# RN831X_RN861X_MCU register map
File version: v0.0.1
CPU: RN831X_RN861X_MCU r1p0, little endian, MPU, no FPU
Registers are 32-bit, read-write, reset 0x0 unless marked. A register's access mark holds for its fields unless they carry their own. Offsets are from the block's base; [hi:lo] are bit positions; {n}, {i} and the like mark numbered series.

## CAN_CORE0 — Controller Area Network Module
Base 0x20058000
Same registers: CAN_CORE1 0xA0058000
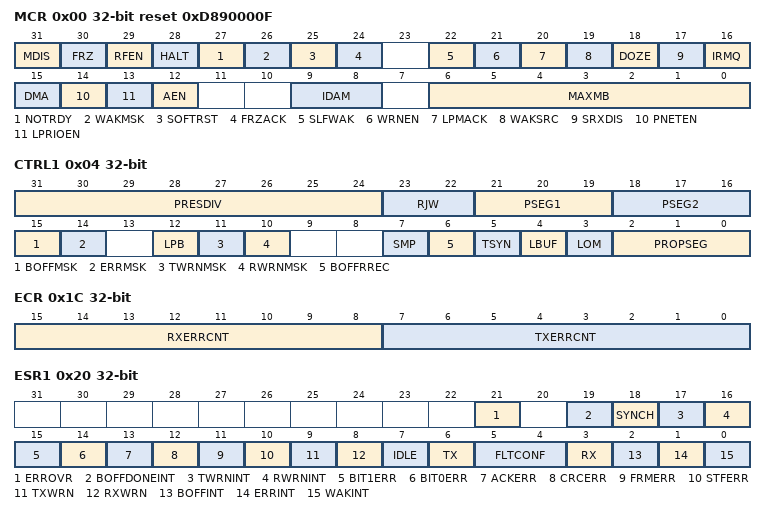
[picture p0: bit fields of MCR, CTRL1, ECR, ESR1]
0x00 MCR reset 0xD890000F — CAN Module Configuration Register.
  [31] MDIS — Disable the CAN module as well as the clocks to the PE and CHI submodules.
  [30] FRZ — Enabled to enter Freeze mode.
  [29] RFEN — Enable Rx FIFO.
  [28] HALT — Enter Freeze mode if the FRZ bit is asserted.
  [27] NOTRDY — CAN is either in Disable or Freeze mode.
  [26] WAKMSK — Enable Wake-up Interrupt.
  [25] SOFTRST — Soft reset.
  [24] FRZACK — Freeze Mode Acknowledge.
  [22] SLFWAK — Wake-up byself Enable.
  [21] WRNEN — Warning Interrupt Enable.
  [20] LPMACK — Low-Power Mode Acknowledge.
  [19] WAKSRC
  [18] DOZE — Enable sleep mode.
  [17] SRXDIS — Disable self reception.
  [16] IRMQ — Enable individual Rx masking and queue feature.
  [15] DMA — Enable DMA feature for Rx FIFO.
  [14] PNETEN — Enable Pretended Network.
  [13] LPRIOEN — Enable Local Priority.
  [12] AEN — Enable abort.
  [9:8] IDAM — The format of the Rx FIFO ID Filter Table elements.
    0=One full ID (standard and extended) per ID Filter Table element; 1=Two full standard IDs or two partial 14-bit extended IDs per ID Filter Table element; 2=Four partial 8-bit standard IDs per ID Filter Table element; 3=All frames rejected
  [6:0] MAXMB — The number of the last MB that will take part in the matching and arbitration processes.
0x04 CTRL1 — CAN Control Register 1.
  [31:24] PRESDIV — Prescaler Division Factor - Defines the ratio between the PE clock frequency and the Serial Clock (Sclock) frequency.
  [23:22] RJW — Resync Jump Width - Defines the maximum number of Tq that a bit time can be changed by one re-synchronization.
  [21:19] PSEG1 — Phase Segment 1 - Defines the length of Phase Segment 1 in the bit time.
  [18:16] PSEG2 — Phase Segment 2 - Defines the length of Phase Segment 2 in the bit time.
  [15] BOFFMSK — Bus Off Interrupt (CAN_ESR1.BOFFINT) Mask.
  [14] ERRMSK — Error Interrupt (CAN_ESR1.ERRINT) Mask.
  [12] LPB — Loop-Back enabled.
  [11] TWRNMSK — Tx Warning Interrupt (CAN_ESR1.TWRNINT) Mask.
  [10] RWRNMSK — Rx Warning Interrupt (CAN_ESR1.RWRNINT) Mask.
  [7] SMP — The sampling mode of CAN bits at the Rx input.
  [6] BOFFRREC — Defines how the CAN recovers from Bus Off state.
  [5] TSYN — Timer Sync - a mechanism that resets the free-running timer each time a message is received in MB0.
  [4] LBUF — The ordering mechanism for message buffer transmission.
  [3] LOM — Configures the CAN to operate in Listen-Only mode.
  [2:0] PROPSEG — Propagation Segment - Defines the length of the Propagation Segment in the bit time.
0x08 TIMER — CAN Free Running Timer Register.
  [15:0] TIMER — Timer Value: Contains the free-running counter value.
0x10 RXMGMASK — CAN Rx Mailboxes Global Mask Register.
  [31:0] MG — Rx Mailboxes Global Mask Bit.
0x14 RX14MASK — CAN Rx14 Mask Register.
  [31:0] RX14M — Rx MB14 Mask Bits.
0x18 RX15MASK — CAN Rx15 Mask Register.
  [31:0] RX15M — Rx MB15 Mask Bits.
0x1C ECR — CAN Error Counter Register.
  [15:8] RXERRCNT — Receive Error Counter - Calculate all errors detected in received messages.
  [7:0] TXERRCNT — Transmit Error Counter - Calculate all errors detected in transmitted messages.
0x20 ESR1 — CAN Error and Status Register 1.
  [21] ERROVR wo write-1-clears — Error Overrun - Indicates that an error condition occurred when any error flag is already set.
  [19] BOFFDONEINT wo write-1-clears — Bus Off Done Interrupt.
  [18] SYNCH ro — CAN Synchronization Status.
  [17] TWRNINT wo write-1-clears — Tx Warning Interrupt Flag.
  [16] RWRNINT wo write-1-clears — Rx Warning Interrupt Flag.
  [15] BIT1ERR ro — Bit1 Error - Indicates when an inconsistency occurs between the transmitted and the received bit in a message.
  [14] BIT0ERR ro — Bit0 Error - Indicates when an inconsistency occurs between the transmitted and the received bit in a message.
  [13] ACKERR ro — Acknowledge Error - Indicates that an Acknowledge Error was detected by the transmitter node (that is, a dominant bit wasn't detected during the ACK SLOT).
  [12] CRCERR ro — Cyclic Redundancy Check Error - Indicates that a CRC Error was detected by the receiver node (that is, the calculated CRC is different from the received CRC).
  [11] FRMERR ro — Form Error - Indicates that a Form Error was detected by the receiver node (that is, a fixed-form bit field contains at least one illegal bit).
  [10] STFERR ro — Stuffing Error - Indicates that a Stuffing Error in a non-FD message or in the arbitration or data phase of a CAN FD message or in the arbitration or data phase of a CAN FD message was detected by the receiver node.
  [9] TXWRN ro — TX Error Warning - Indicates when repetitive errors are occurring during message transmission.
  [8] RXWRN ro — Rx Error Warning - Indicates when repetitive errors are occurring during message reception.
  [7] IDLE ro — CAN bus is in IDLE state.
  [6] TX ro — CAN is transmitting a message.
  [5:4] FLTCONF ro — Fault State of the CAN module.
    0=ERR_ACTIVE (Error Active.); 1=ERR_PASSIVE (Error passive.); 2=BUF_OFF
  [3] RX ro — CAN is receiving a message.
  [2] BOFFINT wo write-1-clears — Bus Off Interrupt.
  [1] ERRINT wo write-1-clears — Error Interrupt.
  [0] WAKINT wo write-1-clears — Wake-up Interrupt.
0x28 IMASK1 — CAN Interrupt Mask Register 1.
  [15:0] BUF15TO0M — MBi Mask Bits - Each bit enables or disables the corresponding interrupt for MB31 to MB0.
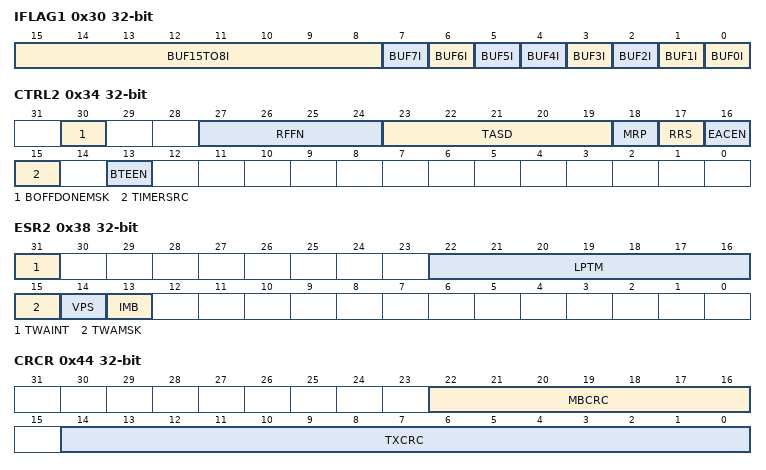
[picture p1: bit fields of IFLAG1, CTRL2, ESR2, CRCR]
0x30 IFLAG1 — CAN Interrupt Flag Register 1.
  [15:8] BUF15TO8I write-1-clears — MBi Interrupt Flag Bits - Each bit flags the corresponding Message Buffer Interrupt for MB15 to MB8.
  [7] BUF7I write-1-clears — MB7 Interrupt or Rx FIFO Overflow.
  [6] BUF6I write-1-clears — MB6 Interrupt or Rx FIFO Warning.
  [5] BUF5I write-1-clears — MB5 Interrupt or Frames Available in Rx FIFO.
  [n] BUF{n}I write-1-clears (n=1..4) — MB{n} Interrupt or Reserved.
  [0] BUF0I write-1-clears — MB0 Interrupt or Clear FIFO bit.
0x34 CTRL2 — CAN Control Register 2.
  [30] BOFFDONEMSK — Bus Off Done Interrupt (CAN_ESR1.BOFFDONEINT) Mask.
  [27:24] RFFN — The number of Rx FIFO filters, as shown in Table 23-12 RFFN must not be programmed with values that make the number of MBs occupied by Rx FIFO and ID Filter exceed the number of mailboxes defined by CAN_MCR.MAXMB.
  [23:19] TASD — Tx Arbitration Start Delay - Indicates how many CAN bits the Tx arbitration process start point can be delayed from the first bit of CRC field on CAN bus. See "23.3.10.6 Tx Arbitration start delay".
  [18] MRP — Mailboxes Reception Priority.
  [17] RRS — Remote Request Storing.
  [16] EACEN — Entire Frame Arbitration Field Comparison Enable For Rx Mailboxes.
  [15] TIMERSRC — Timer Source choice.
  [13] BTEEN — Baudrate Config Type.
0x38 ESR2 ro — CAN Error and Status Register 2.
  [31] TWAINT wo write-1-clears — Time Overflow Interrupt Flag.
  [22:16] LPTM — Lowest Priority Tx Mailbox.
  [15] TWAMSK rw — Time Overflow Interrupt Enable.
  [14] VPS — Indicates whether CAN_ESR2.IMB and CAN_ESR2.LPTM contents are currently valid or not.
  [13] IMB — Inactive Mailbox.
0x44 CRCR ro — CAN CRC Register.
  [22:16] MBCRC — CRC Mailbox - Indicates the number of the mailbox corresponding to the value in the CAN_CRCR.TXCRC field.
  [14:0] TXCRC — Transmitted CRC Value - Indicates the CRC value of the last transmitted message.
0x48 RXFGMASK — CAN Rx FIFO Global Mask Register.
  [31:0] FGM — Rx FIFO Global Mask Bits - Mask the ID Filter Table elements bits.
0x4C RXFIR ro — CAN Rx FIFO Infomation Register.
  [8:0] IDHIT rw — ID Acceptance Filter Hit Indicator - Indicates which ID Acceptance Filter (IDAF) was hit by the received message in the Rx FIFO.
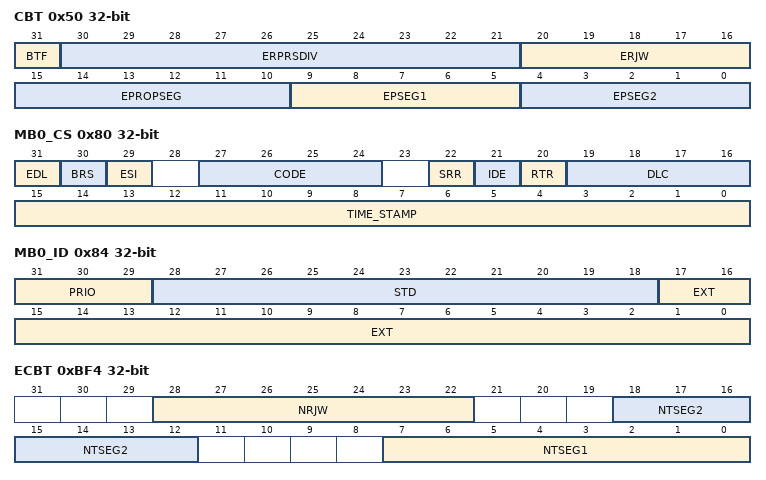
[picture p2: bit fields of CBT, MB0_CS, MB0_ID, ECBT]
0x50 CBT — CAN Bit Timing Register.
  [31] BTF — Bit Timing Format - Enables the use of extended CAN bit timing fields EPRESDIV, EPROPSEG, EPSEG1, EPSEG2 and ERJW, replacing the CAN bit timing variables defined in CAN_CTRL1.
  [30:21] ERPRSDIV — Extended Prescaler Division Factor.
  [20:16] ERJW — Extended Resync Jump Width.
  [15:10] EPROPSEG — Extended Propagation Segment.
  [9:5] EPSEG1 — Extended Phase Segment 1.
  [4:0] EPSEG2 — Extended Phase Segment 2.
0x80 MB0_CS — CAN Mailbox 0 CS Register.
  [31] EDL
  [30] BRS
  [29] ESI — Error Status in Tx.
  [27:24] CODE — Mailbox Code Field.
    1=0; 2=1; 4=2; 8=3
  [22] SRR — Substitute Remote Request.
  [21] IDE — ID type.
  [20] RTR — Remote Transmission Request.
  [19:16] DLC — Data Length Code.
    1=0; 2=1; 4=2; 8=3
  [15:0] TIME_STAMP
    1=0; 2=1; 4=2; 8=3; 16=4; 32=5; 64=6; 128=7; 0x100=8; 0x200=9; 0x400=10; 0x800=11; 0x1000=12; 0x2000=13; 0x4000=14; 0x8000=15
0x84 MB0_ID — CAN Mailbox 0 ID Register.
  [31:29] PRIO
  [28:18] STD
    1=0; 2=1; 4=2; 8=3; 16=4; 32=5; 64=6; 128=7; 0x100=8; 0x200=9; 0x400=10
  [17:0] EXT
    1=0; 2=1; 4=2; 8=3; 16=4; 32=5; 64=6; 128=7; 0x100=8; 0x200=9; 0x400=10; 0x800=11; 0x1000=12; 0x2000=13; 0x4000=14; 0x8000=15; 0x10000=16; 0x20000=17
{0x88+0x10*i} MB{i}_WORD0 (i=0..15) — CAN Mailbox {i} Word Register.
  [31:0] DATA
{0x8C+0x10*i} MB{i}_WORD1 (i=0..5) — CAN Mailbox {i} Word Register.
  [31:0] DATA
{0x80+0x10*i} MB{i}_CS (i=1..15) — CAN Mailbox {i} CS Register.
{0x84+0x10*i} MB{i}_ID (i=1..15) — CAN Mailbox {i} ID Register.
0xEC MB6_WORD1 — CAN Mailbox 7 Word Register.
  [31:0] DATA
{0x8C+0x10*i} MB{i}_WORD1 (i=7..15) — CAN Mailbox {i} Word Register.
  [31:0] DATA
0x880 RXIMR0 — CAN Rx Individual Mask Register 0.
  [31:0] MI — Individual Mask Bits.
{0x880+4i} RXIMR{i} (i=1..15) — CAN Rx Individual Mask Register {i}.
0xBF0 EPRS — CAN Enhanced Pre-allocated Bit Timing Setting Register.
  [9:0] ENPRESDIV
0xBF4 ECBT — CAN Enhanced Pre-allocated Bit Timing Paramaters Configuration Register.
  [28:22] NRJW — Resynchronization jump width
  [18:12] NTSEG2 — Phase Buffer Segment 2
  [7:0] NTSEG1 — Phase Buffer Segment 1
0x3200 DMA_RBADR — CAN DMA Rx Beginning Address Register.
  [17:0] ADDR
0x3204 DMA_RLEN — CAN DMA Rx Data Length Register.
  [17:0] LEN
0x3208 DMA_RADR ro — CAN DMA Current Address Register.
  [17:0] ADDR
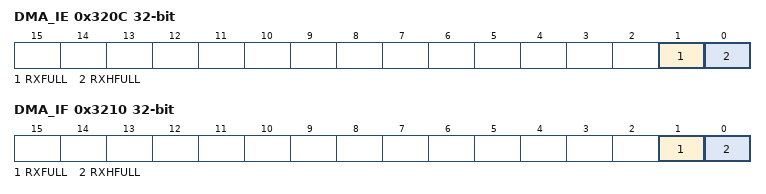
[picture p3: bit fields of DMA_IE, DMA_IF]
0x320C DMA_IE — CAN DMA Interrupt Enable Register.
  [1] RXFULL — Rx Full Mask Bits.
  [0] RXHFULL — Rx Half-Full Mask Bits.
0x3210 DMA_IF — CAN DMA Interrupt Flag Register.
  [1] RXFULL write-1-clears — Rx Full Mask Bits.
  [0] RXHFULL write-1-clears — Rx Half-Full Mask Bits.
0x3214 TMR_SEL — CAN Timer Filter Select Register.
  [0] FILTER
0x3218 STOP_MD — CAN Stop Mode Register.
  [31:0] PWD
